# trimsir_me17 register map
Registers are access not given, no defined reset value unless marked. A register's access mark holds for its fields unless they carry their own. Offsets are from the block's base; lines under a group give offsets from that group; [hi:lo] are bit positions; {n}, {i} and the like mark numbered series; 'fields as' and 'values as' point back to an identical list; <NAME> marks a mode.

## Memory map
0x40005400 TRIMSIR size 0x400 — Trim System Initilazation Registers

## TRIMSIR — Trim System Initilazation Registers
Base 0x40005400
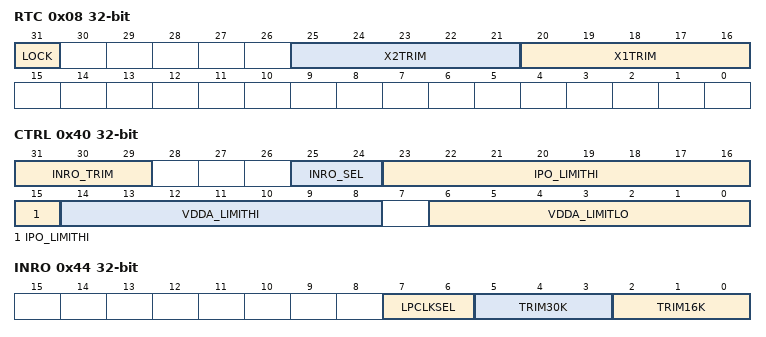
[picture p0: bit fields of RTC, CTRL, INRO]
0x08 RTC — RTC Trim System Initialization Register.
  [31] LOCK
  [25:21] X2TRIM — RTC X2 Trim.
  [20:16] X1TRIM — RTC X1 Trim.
0x34 SIMO ro — SIMO Trim System Initialization Register.
  [2:0] CLKDIV — SIMO Clock Divide.
    0=DIV1; 1=DIV16; 3=DIV32; 5=DIV64; 7=DIV128
0x3C IPOLO ro — IPO Low Trim System Initialization Register.
  [7:0] IPO_LIMITLO — IPO Low Limit Trim.
0x40 CTRL — Control Trim System Initialization Register.
  [31:29] INRO_TRIM — INRO Clock Trim.
  [25:24] INRO_SEL — INRO Clock Select.
    0=8KHZ; 1=16KHZ; 2=30KHZ
  [23:15] IPO_LIMITHI — IPO High Trim Limit.
  [14:8] VDDA_LIMITHI — VDDA High Trim Limit.
  [6:0] VDDA_LIMITLO — VDDA Low Trim Limit.
0x44 INRO — RTC Trim System Initialization Register.
  [7:6] LPCLKSEL — INRO Low Power Mode Clock Select.
    0=8KHZ; 1=16KHZ; 2=30KHZ
  [5:3] TRIM30K — INRO 30KHz Trim.
  [2:0] TRIM16K — INRO 16KHz Trim.
